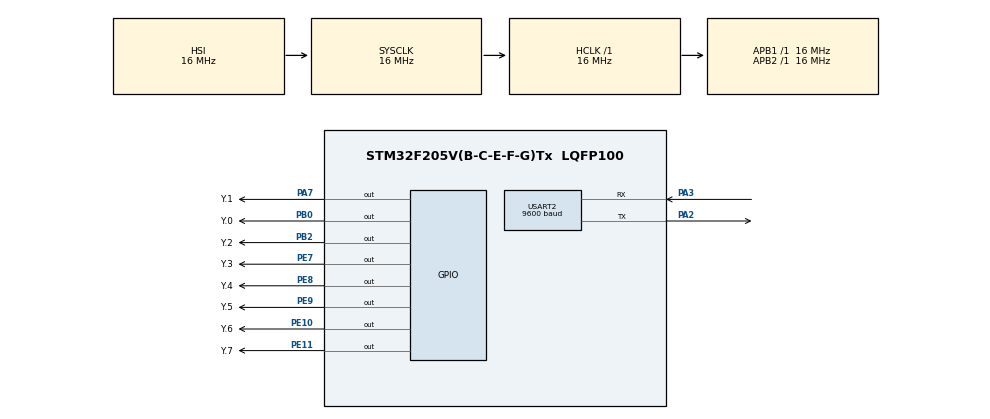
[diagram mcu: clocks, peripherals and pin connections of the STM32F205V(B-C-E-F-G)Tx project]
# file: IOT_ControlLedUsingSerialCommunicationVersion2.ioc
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Mcu.Family=STM32F2
Mcu.Name=STM32F205V(B-C-E-F-G)Tx
Mcu.Package=LQFP100
NVIC.PriorityGroup=NVIC_PRIORITYGROUP_4
NVIC.USART2_IRQn=true\:0\:0\:false\:false\:true\:true\:true\:true
PA13.Mode=Serial_Wire
PA13.Signal=SYS_JTMS-SWDIO
PA14.Mode=Serial_Wire
PA14.Signal=SYS_JTCK-SWCLK
PA2.Mode=Asynchronous
PA2.Signal=USART2_TX
PA3.Mode=Asynchronous
PA3.Signal=USART2_RX
PA7.GPIO_Label=Y.1
PA7.PinState=GPIO_PIN_SET
PA7.Signal=GPIO_Output
PB0.GPIO_Label=Y.0
PB0.PinState=GPIO_PIN_SET
PB0.Signal=GPIO_Output
PB2.GPIO_Label=Y.2
PB2.PinState=GPIO_PIN_SET
PB2.Signal=GPIO_Output
PE10.GPIO_Label=Y.6
PE10.PinState=GPIO_PIN_SET
PE10.Signal=GPIO_Output
PE11.GPIO_Label=Y.7
PE11.PinState=GPIO_PIN_SET
PE11.Signal=GPIO_Output
PE7.GPIO_Label=Y.3
PE7.PinState=GPIO_PIN_SET
PE7.Signal=GPIO_Output
PE8.GPIO_Label=Y.4
PE8.PinState=GPIO_PIN_SET
PE8.Signal=GPIO_Output
PE9.GPIO_Label=Y.5
PE9.PinState=GPIO_PIN_SET
PE9.Signal=GPIO_Output
ProjectManager.HeapSize=0x200
ProjectManager.StackSize=0x400
ProjectManager.TargetToolchain=MDK-ARM V5.27
RCC.48MHZClocksFreq_Value=48000000
RCC.AHBFreq_Value=16000000
RCC.APB1Freq_Value=16000000
RCC.APB2Freq_Value=16000000
RCC.CortexFreq_Value=16000000
RCC.HSE_VALUE=25000000
RCC.HSI_VALUE=16000000
RCC.LSE_VALUE=32768
RCC.SYSCLKFreq_VALUE=16000000
RCC.VCOOutputFreq_Value=192000000
USART2.BaudRate=9600
USART2.VirtualMode=VM_ASYNC
board=custom

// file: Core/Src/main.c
/* USER CODE BEGIN Header */
/**
  ******************************************************************************
  * @file           : main.c
  * @brief          : Main program body
  ******************************************************************************
  * @attention
  *
  * Copyright (c) 2023 STMicroelectronics.
  * All rights reserved.
  *
  * This software is licensed under terms that can be found in the LICENSE file
  * in the root directory of this software component.
  * If no LICENSE file comes with this software, it is provided AS-IS.
  *
  ******************************************************************************
  */
/* USER CODE END Header */
#include "main.h"

UART_HandleTypeDef huart2;

/* USER CODE BEGIN PV */
uint8_t RxBuff[1];
/* USER CODE END PV */

void SystemClock_Config(void);
static void MX_GPIO_Init(void);
static void MX_USART2_UART_Init(void);

int main(void)
{

  /* MCU Configuration--------------------------------------------------------*/

  /* Reset of all peripherals, Initializes the Flash interface and the Systick. */
  HAL_Init();

  /* Configure the system clock */
  SystemClock_Config();

  /* Initialize all configured peripherals */
  MX_GPIO_Init();
  MX_USART2_UART_Init();
  /* USER CODE BEGIN 2 */
	HAL_UART_Receive_IT(&huart2, RxBuff, sizeof(RxBuff));
  /* USER CODE END 2 */

  /* Infinite loop */
  while (1)
  {
		switch (RxBuff[0]){
			case '1':
				HAL_GPIO_WritePin(GPIOB ,GPIO_PIN_0, 0);
			break;
			case '2':
				HAL_GPIO_WritePin(GPIOA ,GPIO_PIN_7, 0);
			break;
			case '3':
				HAL_GPIO_WritePin(GPIOB ,GPIO_PIN_2, 0);

			break;
			case '4':
				HAL_GPIO_WritePin(GPIOE ,GPIO_PIN_7, 0);

			break;
			case '5':
				HAL_GPIO_WritePin(GPIOE ,GPIO_PIN_8, 0);

			break;
			case '6':
				HAL_GPIO_WritePin(GPIOE ,GPIO_PIN_9, 0);

			break;
			case '7':
				HAL_GPIO_WritePin(GPIOE ,GPIO_PIN_10, 0);

			break;
			case '8':
				HAL_GPIO_WritePin(GPIOE ,GPIO_PIN_11, 0);

			break;
			case 'a':
				HAL_GPIO_WritePin(GPIOB ,GPIO_PIN_0, 1);

			break;
			case 'b':
				HAL_GPIO_WritePin(GPIOA ,GPIO_PIN_7, 1);

			break;
			case 'c':
				HAL_GPIO_WritePin(GPIOB ,GPIO_PIN_2, 1);

			break;
			case 'd':
				HAL_GPIO_WritePin(GPIOE ,GPIO_PIN_7, 1);

			break;
			case 'e':
				HAL_GPIO_WritePin(GPIOE ,GPIO_PIN_8, 1);

			break;
			case 'f':
				HAL_GPIO_WritePin(GPIOE ,GPIO_PIN_9, 1);

			break;
			case 'g':
				HAL_GPIO_WritePin(GPIOE ,GPIO_PIN_10, 1);

			break;
			case 'h':
				HAL_GPIO_WritePin(GPIOE ,GPIO_PIN_11, 1);

			break;

		}
  }
}

void SystemClock_Config(void)
{
  RCC_OscInitTypeDef RCC_OscInitStruct = {0};
  RCC_ClkInitTypeDef RCC_ClkInitStruct = {0};

  /** Initializes the RCC Oscillators according to the specified parameters
  * in the RCC_OscInitTypeDef structure.
  */
  RCC_OscInitStruct.OscillatorType = RCC_OSCILLATORTYPE_HSI;
  RCC_OscInitStruct.HSIState = RCC_HSI_ON;
  RCC_OscInitStruct.HSICalibrationValue = RCC_HSICALIBRATION_DEFAULT;
  RCC_OscInitStruct.PLL.PLLState = RCC_PLL_NONE;
  if (HAL_RCC_OscConfig(&RCC_OscInitStruct) != HAL_OK)
  {
    Error_Handler();
  }

  /** Initializes the CPU, AHB and APB buses clocks
  */
  RCC_ClkInitStruct.ClockType = RCC_CLOCKTYPE_HCLK|RCC_CLOCKTYPE_SYSCLK
                              |RCC_CLOCKTYPE_PCLK1|RCC_CLOCKTYPE_PCLK2;
  RCC_ClkInitStruct.SYSCLKSource = RCC_SYSCLKSOURCE_HSI;
  RCC_ClkInitStruct.AHBCLKDivider = RCC_SYSCLK_DIV1;
  RCC_ClkInitStruct.APB1CLKDivider = RCC_HCLK_DIV1;
  RCC_ClkInitStruct.APB2CLKDivider = RCC_HCLK_DIV1;

  if (HAL_RCC_ClockConfig(&RCC_ClkInitStruct, FLASH_LATENCY_0) != HAL_OK)
  {
    Error_Handler();
  }
}

static void MX_USART2_UART_Init(void)
{

  huart2.Instance = USART2;
  huart2.Init.BaudRate = 9600;
  huart2.Init.WordLength = UART_WORDLENGTH_8B;
  huart2.Init.StopBits = UART_STOPBITS_1;
  huart2.Init.Parity = UART_PARITY_NONE;
  huart2.Init.Mode = UART_MODE_TX_RX;
  huart2.Init.HwFlowCtl = UART_HWCONTROL_NONE;
  huart2.Init.OverSampling = UART_OVERSAMPLING_16;
  if (HAL_UART_Init(&huart2) != HAL_OK)
  {
    Error_Handler();
  }

}

static void MX_GPIO_Init(void)
{
  GPIO_InitTypeDef GPIO_InitStruct = {0};

  /* GPIO Ports Clock Enable */
  __HAL_RCC_GPIOA_CLK_ENABLE();
  __HAL_RCC_GPIOB_CLK_ENABLE();
  __HAL_RCC_GPIOE_CLK_ENABLE();

  /*Configure GPIO pin Output Level */
  HAL_GPIO_WritePin(Y_1_GPIO_Port, Y_1_Pin, GPIO_PIN_SET);

  /*Configure GPIO pin Output Level */
  HAL_GPIO_WritePin(GPIOB, Y_0_Pin|Y_2_Pin, GPIO_PIN_SET);

  /*Configure GPIO pin Output Level */
  HAL_GPIO_WritePin(GPIOE, Y_3_Pin|Y_4_Pin|Y_5_Pin|Y_6_Pin
                          |Y_7_Pin, GPIO_PIN_SET);

  /*Configure GPIO pin : Y_1_Pin */
  GPIO_InitStruct.Pin = Y_1_Pin;
  GPIO_InitStruct.Mode = GPIO_MODE_OUTPUT_PP;
  GPIO_InitStruct.Pull = GPIO_NOPULL;
  GPIO_InitStruct.Speed = GPIO_SPEED_FREQ_LOW;
  HAL_GPIO_Init(Y_1_GPIO_Port, &GPIO_InitStruct);

  /*Configure GPIO pins : Y_0_Pin Y_2_Pin */
  GPIO_InitStruct.Pin = Y_0_Pin|Y_2_Pin;
  GPIO_InitStruct.Mode = GPIO_MODE_OUTPUT_PP;
  GPIO_InitStruct.Pull = GPIO_NOPULL;
  GPIO_InitStruct.Speed = GPIO_SPEED_FREQ_LOW;
  HAL_GPIO_Init(GPIOB, &GPIO_InitStruct);

  /*Configure GPIO pins : Y_3_Pin Y_4_Pin Y_5_Pin Y_6_Pin
                           Y_7_Pin */
  GPIO_InitStruct.Pin = Y_3_Pin|Y_4_Pin|Y_5_Pin|Y_6_Pin
                          |Y_7_Pin;
  GPIO_InitStruct.Mode = GPIO_MODE_OUTPUT_PP;
  GPIO_InitStruct.Pull = GPIO_NOPULL;
  GPIO_InitStruct.Speed = GPIO_SPEED_FREQ_LOW;
  HAL_GPIO_Init(GPIOE, &GPIO_InitStruct);

}

/* USER CODE BEGIN 4 */
void HAL_UART_RxCpltCallback(UART_HandleTypeDef *huart){
	if (huart-> Instance==USART2)
	{
		HAL_UART_Receive_IT(&huart2, RxBuff ,sizeof(RxBuff));
	}
}
/* USER CODE END 4 */

void Error_Handler(void)
{
  __disable_irq();
  while (1)
  {
  }
}
